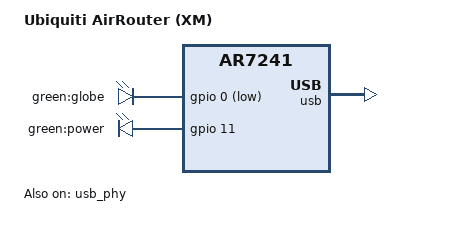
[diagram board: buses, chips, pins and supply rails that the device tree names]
// SPDX-License-Identifier: GPL-2.0-or-later OR MIT

#include "ar7241.dtsi"
#include "ar724x_ubnt_xm.dtsi"

/ {
	compatible = "ubnt,airrouter", "ubnt,xm", "qca,ar7241";
	model = "Ubiquiti AirRouter (XM)";

	aliases {
		led-boot = &led_globe;
		led-failsafe = &led_globe;
		led-running = &led_globe;
		led-upgrade = &led_globe;
		label-mac-device = &wifi;
	};

	leds {
		compatible = "gpio-leds";

		led_globe: globe {
			label = "green:globe";
			gpios = <&gpio 0 GPIO_ACTIVE_LOW>;
		};

		power {
			label = "green:power";
			gpios = <&gpio 11 GPIO_ACTIVE_HIGH>;
		};
	};
};

&usb_phy {
	status = "okay";
};

&usb {
	status = "okay";
};
